# psc3_p8_ppca register map
Vendor: Infineon Technologies; Series: PSC3_P8; File version: 1.0
CPU: CM33 r0p1, little endian, MPU, FPU, DSP, VTOR, 3 interrupt priority bits, 143 interrupts
Registers are 32-bit, read-write, reset 0x0 unless marked. A register's access mark holds for its fields unless they carry their own. Offsets are from the block's base; [hi:lo] are bit positions; lines under a group give offsets from that group; {n}, {i} and the like mark numbered series.

## RAMC0 — RAMC0/1/2
Base 0x68110000
Same registers: RAMC1 0x68120000
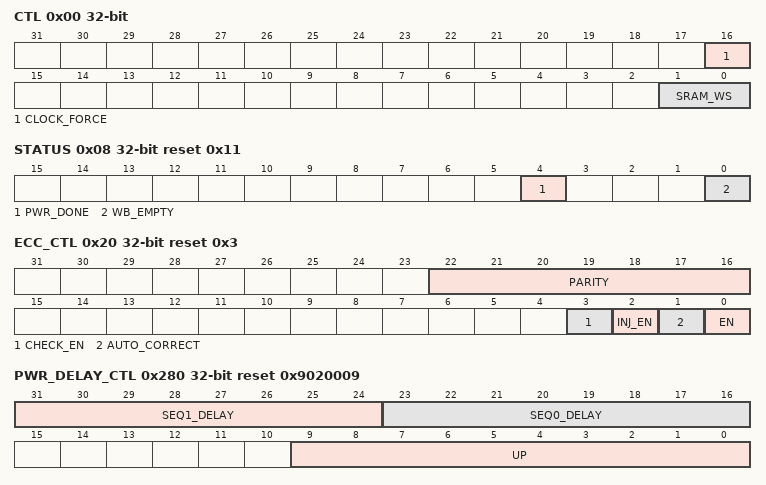
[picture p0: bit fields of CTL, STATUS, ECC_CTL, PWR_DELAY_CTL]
0x00 CTL — Control
  [16] CLOCK_FORCE — Force EAM clock gating to be always ON. 0: Disabled 1: Enabled This bit provides fail safe mechanism for dynamic clock gating added on EAM block.
  [1:0] SRAM_WS — Wait states.
    {v}=WS_{v} (N/A) (v=0..3)
0x08 STATUS ro reset 0x11
  [4] PWR_DONE — After a PWR_MACRO_CTL.OFF change this flag indicates if the new power mode has taken effect or not. 1: Indicates change is effective; 0: Indicates change is in progress;
  [0] WB_EMPTY — Write buffer empty. This information is used when entering DeepSleep power mode: WB_EMPTY must be '1' before a transition to system DeepSleep power mode. '0': Write buffer NOT empty. '1': Write buffer empty. Note: the SRAM controller write buffer is only used when ECC checking is enabled. (RAMi_CTL.ECC_EN is '1').
0x20 ECC_CTL reset 0x3 — ECC control
  [22:16] PARITY — Injected parity.
  [3] CHECK_EN — ECC checking enable: '0': Disabled. No ECC checking and associated bus errors. No fault reporting. Intended for SRAM initialization. '1': Enabled. Note: This field is ignored when EN is '0'.
  [2] INJ_EN — ECC parity injection: '0': Disabled. '1': Enabled. Instead of calculating the parity from the transfer's write data, the parity is taken from PARITY upon a match of the transfer's write address with ECC_MATCH.WORD_ADDR (no match is performed on the transfer's write strobes/mask). Note: Parity injection invalidates the write buffer for this word address. If only a part of 64-bit data word is written AND consistency should be maintained, STATUS.ALL_WB_EMPTY is '1' should be checked before. Note: This field is ignored when EN is '0'.
  [1] AUTO_CORRECT — ECC auto correction: '0': Disabled. Corrected ECC errors are ONLY HW corrected 'on-the-fly' (not corrected in the SRAM). Fault reporting is enabled. '1': Enabled. Correctable ECC errors are HW corrected 'on-the-fly' and in the SRAM, without CPU intervention. Fault reporting is enabled. Note: This field is ignored when EN is '0' or when CHECK_EN is '0'.
  [0] EN — ECC enable: '0': Disabled. '1': Enabled.
    0=ECC_DISABLED (N/A); 1=ECC_ENABLED (N/A)
0x24 ECC_STATUS0 ro reset not defined
  [31:0] ADDR — ECC error address. This register captures the address location when ECC error happens.
0x28 ECC_STATUS1 ro reset not defined
  [6:0] SYNDROME — This register captures the ECC syndrome when ECC error happens.
0x104 ECC_MATCH
  [24:0] WORD_ADDR — Specifies the word address where an error will be injected. - On a write transfer to this SRAM address and when the ECC_CTL.INJ_EN bit is '1', the parity (ECC_CTL.PARITY) is injected.
0x200 PWR_MACRO_CTL — SRAM power partition power control
  [31:0] OFF — Each bit represent the individual RAM power partition power state. One bit for each macro of RAM controller when all 32 bits are populated as 32 independent power partitions. 0: Macros in power partion is to be powered-ON 1: Macros in power partion is to be powered-OFF Note 1: it is not allowed to disable a macro during access to its address range. Note 2: it is not allowed to disable few macros while enable others in the same AHB write transaction. It is mandatory to check for STATUS.PWR_DONE to become 1 once this PWR_MACRO_DTL register contents are changed to ensure SRAM mode transition is completed successfully.
0x240 PWR_MACRO_CTL_LOCK reset 0x3 — SRAM power partition power control Lock
  [1:0] PWR_MACRO_CTL_LOCK — Prohibits Read/Write access to PWR_MACRO_CTL register when this field is not equal to 0. Requires at least two different writes to unlock. Note that this field is 2 bits to force multiple writes only. By default AHB reads/writes to PWR_MACRO_CTL register are locked.
    0=NO_CHG (No effect); 1=CLR0 (Clears bit 0); 2=CLR1 (Clears bit 1); 3=SET01 (Sets both bits 0 and 1)
0x280 PWR_DELAY_CTL reset 0x9020009 — SRAM power switch power up & sequence delay
  [31:24] SEQ1_DELAY — Number of IMO clock cycles delay needed for sequence-1 of SRAM power transition
  [23:16] SEQ0_DELAY — Number of IMO clock cycles delay needed for sequence-0 of SRAM power transition
  [9:0] UP — Number of IMO clock cycles delay needed after power domain power up
0x4000 MPC group — MPC Memory Protection Controller registers
  0x00 CFG — Config register with error response, RegionID PPC_MPC_MAIN is the security owner PC. The error response configuration is located in CFG.RESPONSE, only one such configuration exists applying to all protection contexts in the system.
    [4] RESPONSE — Response Configuration for Security and PC violations 0: Read-Zero Write Ignore (RAZ/WI) 1: Bus Error
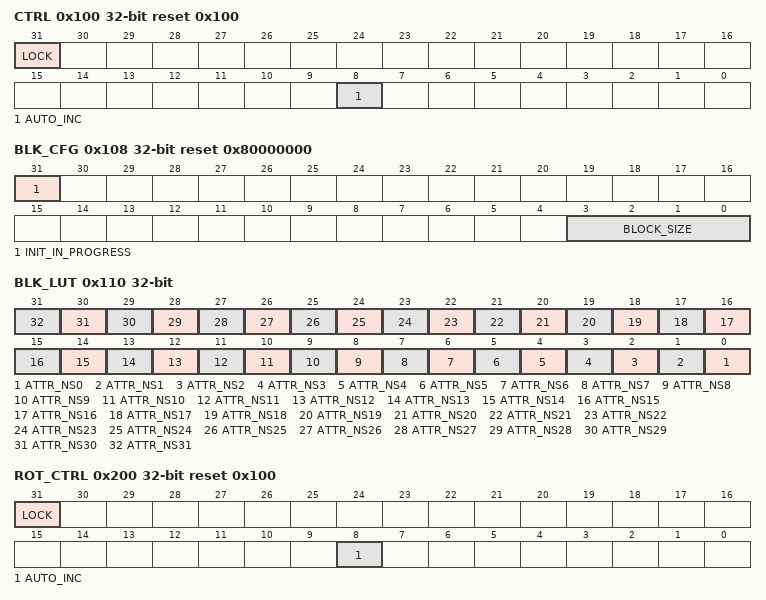
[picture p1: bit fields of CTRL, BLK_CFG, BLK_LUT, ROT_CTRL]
  0x100 CTRL reset 0x100 — Control register with lock bit and auto-increment only (Separate CTRL for each PC depends on access_pc)
    [31] LOCK write-1-sets — Security lockdown for this protection context. Software can set this bit but not clear it once set. When set, write operations to BLK_LUT are not possible from this protection context. Setting LOCK also blocks writes to CTRL itself (for that PC copy). All writes are ignored.
    [8] AUTO_INC — Auto-increment BLK_IDX by 1 for this protection context as a side effect of each read/write access to BLK_LUT
  0x104 BLK_MAX ro — Max value of block-based index register
    [31:0] VALUE — Maximum value of block-based index register. The number and size blocks in an MPC is design time configurable and for embedded memories defaults to covering the entire memory using 4kB blocks; See product datasheet for details on protection of external memories.
  0x108 BLK_CFG ro reset 0x80000000 — Block size & initialization in progress
    [31] INIT_IN_PROGRESS — During initialization INIT_IN_PROGRESS is '1' and MMIO register accesses to BLK_LUT is blocked (BLK_IDX increment is also ignored). The block attributes are retained in DeepSleep (and obviously Active) power mode. Initialization is only required from a power mode in which the block attributes are not retained. E.g., initialization is required for a cold boot (after a Power-on-Reset). HW initializes the block attributes: the NS attributes are set to '0' (secure), the R attributes are set to '1' (read access allowed) and the W attributes are set to '1' (write access allowed). During initialization, the MPC supports memory accesses (memory accesses are NOT blocked) with the initialization block attribute values as mentioned above. This e.g. allows MPC initialization to proceed in parallel with boot program memory accesses (as opposed to serializing the two), improving device boot time.
    [3:0] BLOCK_SIZE — Block size of individually protected blocks (0: 32B, 1: 64B, ... up to 15: 1MB) Block size= (1<<(BLOCK_SIZE+5)) The number and size blocks in an MPC is design time configurable and for embedded memories defaults to covering the entire memory using 4kB blocks; see product datasheet for details on protection of external memories.
  0x10C BLK_IDX — Index of 32-block group accessed through BLK_LUT (Separate IDX for each PC depending on access_pc)
    [31:0] VALUE — Index value for accessing block-based lookup table using BLK_LUT. Programming out of LUT range is an user error and it loops back to '0' once overflow occurs.
  0x110 BLK_LUT — NS status for 32 blocks at BLK_IDX with PC=<access_pc>
    [n] ATTR_NS{n} (n=0..31) — NS bit for block {n} based on BLK_IDX
  0x200 ROT_CTRL reset 0x100 — Control register with lock bit and auto-increment only
    [31] LOCK write-1-sets — Security lockdown for the root-of-trust configuration registers. Software can set this bit but not clear it once set. When set, write operations to ROT_BLK_LUT are not possible. Write is ignored.
    [8] AUTO_INC — Auto-increment ROT_BLK_IDX by 1 for each read/write of ROT_BLK_LUT
  0x208 ROT_BLK_MAX ro — Max value of block-based index register for ROT
    [31:0] VALUE — Maximum value of block-based index register. The number and size blocks in an MPC is design time configurable and for embedded memories defaults to covering the entire memory using 4kB blocks; see product datasheet for details on protection of external memories.
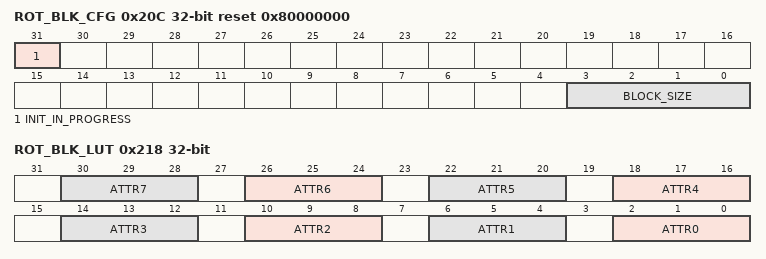
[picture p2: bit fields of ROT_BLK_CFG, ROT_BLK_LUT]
  0x20C ROT_BLK_CFG ro reset 0x80000000 — Same as BLK_CFG
    [31] INIT_IN_PROGRESS — During initialization INIT_IN_PROGRESS is '1' and MMIO register accesses to ROT_BLK_LUT is RAZWI. The block attributes are retained in DeepSleep (and obviously Active) power mode. Initialization is only required from a power mode in which the block attributes are not retained. E.g., initialization is required for a cold boot (after a Power-on-Reset). HW initializes the block attributes: the NS attributes are set to '0' (secure), the R attributes are set to '1' (read access allowed) and the W attributes are set to '1' (write access allowed). During initialization, the MPC supports memory accesses (memory accesses are NOT blocked) with the initialization block attribute values as mentioned above. This e.g. allows MPC initialization to proceed in parallel with boot program memory accesses (as opposed to serializing the two), improving device boot time.
    [3:0] BLOCK_SIZE — Block size of individually protected blocks (0: 32B, 1: 64B, ...up to 15:1MB) Block size= (1<<(BLOCK_SIZE+5)) The number and size blocks in an MPC is design time configurable and for embedded memories defaults to covering the entire memory using 4kB blocks; see product datasheet for details on protection of external memories.
  0x210 ROT_BLK_IDX — Index of 8-block group accessed through ROT_BLK_LUT_*
    [31:0] VALUE — Index value for accessing block-based lookup table using ROT_BLK_LUT. Programming out of LUT range is an user error and it loops back to '0' once overflow occurs.
  0x214 ROT_BLK_PC — Protection context of 8-block group accesses through ROT_BLK_LUT
    [3:0] PC — Specify PC values for ROT_BLK_IDX and ROT_BLK_LUT
  0x218 ROT_BLK_LUT — (R,W,NS) bits for 8 blocks at ROT_BLK_IDX for PC=ROT_BKL_PC
    [4n+2:4n] ATTR{n} (n=0..7) — W/R/NS bits for block {n} indicated by ROT_BLK_IDX for ROT_BLK_PC PC

## Notices in the file
(c) 2016-2026, Infineon Technologies AG or an affiliate of
Infineon Technologies AG.
SPDX-License-Identifier: Apache-2.0
Licensed under the Apache License, Version 2.0 (the "License");
you may not use this file except in compliance with the License.
You may obtain a copy of the License at
http://www.apache.org/licenses/LICENSE-2.0
Unless required by applicable law or agreed to in writing, software
distributed under the License is distributed on an "AS IS" BASIS,
WITHOUT WARRANTIES OR CONDITIONS OF ANY KIND, either express or implied.
See the License for the specific language governing permissions and
limitations under the License.
